# GD32VF103 register map
File version: 1.0
CPU: r2p1, little endian, no MPU, no FPU, 4 interrupt priority bits
Registers are 32-bit, read-write, reset 0x0 unless marked. A register's access mark holds for its fields unless they carry their own. Offsets are from the block's base; [hi:lo] are bit positions; {n}, {i} and the like mark numbered series.

## CPU_TIMER
Base 0xD1000000
0x00 MTIME_LO — mtime low register
  [31:0] COUNT — MTIME count
0x04 MTIME_HI — mtime high register
  [31:0] COUNT — MTIME count
0x08 MTIMECMP_LO reset 0xFFFFFFFF — mtimecmp low register
  [31:0] COUNT — MTIMECMP count
0x0C MTIMECMP_HI reset 0xFFFFFFFF — mtimecmp high register
  [31:0] COUNT — MTIMECMP count
0xFF8 MSTOP
  [0] TIMESTOP
0xFFC MSIP
  [0] MSIP

## ECLIC — Enhanced Core Local Interrupt Controller
Base 0xD2000000
0x00 CLICCFG 8-bit
  [4:1] NLBITS
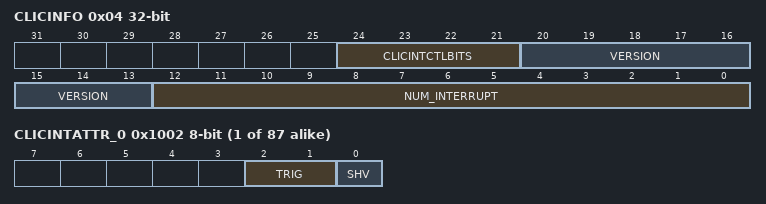
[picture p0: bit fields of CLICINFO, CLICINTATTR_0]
0x04 CLICINFO ro
  [24:21] CLICINTCTLBITS, [20:13] VERSION, [12:0] NUM_INTERRUPT
0x0B MTH 8-bit
{0x1000+4i} CLICINTIP_{i} 8-bit (i=0..84) — clicintip Register
  [0] IP
{0x1001+4i} CLICINTIE_{i} 8-bit (i=0..86) — clicintie Register
  [0] IE
{0x1002+4i} CLICINTATTR_{i} 8-bit (i=0..86) — clicintattr Register
  [2:1] TRIG, [0] SHV
{0x1003+4i} CLICINTCTL_{i} 8-bit (i=0..86) — clicintctl Register
  [7:0] LEVEL_PRIORITY
0x1158 CLICINTIP_85 8-bit — clicintip Register
  [0] IP
0x115C CLICINTIP_86 8-bit — clicintip Register
  [0] IP

## PMU — Power management unit
Base 0x40007000
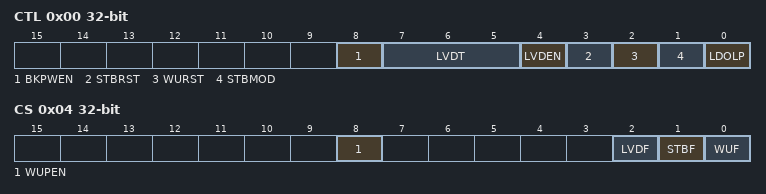
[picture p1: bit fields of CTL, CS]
0x00 CTL — power control register
  [8] BKPWEN — Backup Domain Write Enable
  [7:5] LVDT — Low Voltage Detector Threshold
  [4] LVDEN — Low Voltage Detector Enable
  [3] STBRST — Standby Flag Reset
  [2] WURST — Wakeup Flag Reset
  [1] STBMOD — Standby Mode
  [0] LDOLP — LDO Low Power Mode
0x04 CS access per field — power control/status register
  [8] WUPEN rw — Enable WKUP pin
  [2] LVDF ro — Low Voltage Detector Status Flag
  [1] STBF ro — Standby flag
  [0] WUF ro — Wakeup flag

## RTC — Real-time clock
Base 0x40002800
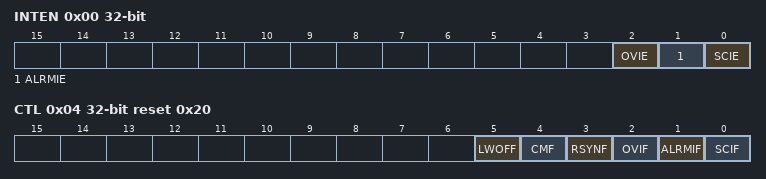
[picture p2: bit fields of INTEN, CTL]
0x00 INTEN — RTC interrupt enable register
  [2] OVIE — Overflow interrupt enable
  [1] ALRMIE — Alarm interrupt enable
  [0] SCIE — Second interrupt
0x04 CTL reset 0x20 — control register
  [5] LWOFF — Last write operation finished flag
  [4] CMF — Configuration mode flag
  [3] RSYNF — Registers synchronized flag
  [2] OVIF — Overflow interrupt flag
  [1] ALRMIF — Alarm interrupt flag
  [0] SCIF — Sencond interrupt flag
0x08 PSCH write — RTC prescaler high register
  [3:0] PSC — RTC prescaler value high
0x0C PSCL write reset 0x8000 — RTC prescaler low register
  [15:0] PSC — RTC prescaler value low
0x10 DIVH ro — RTC divider high register
  [3:0] DIV — RTC divider value high
0x14 DIVL ro reset 0x8000 — RTC divider low register
  [15:0] DIV — RTC divider value low
0x18 CNTH — RTC counter high register
  [15:0] CNT — RTC counter value high
0x1C CNTL — RTC counter low register
  [15:0] CNT — RTC counter value low
0x20 ALRMH write reset 0xFFFF — Alarm high register
  [15:0] ALRM — Alarm value high
0x24 ALRML write reset 0xFFFF — RTC alarm low register
  [15:0] ALRM — alarm value low

## SPI0 — Serial peripheral interface
Base 0x40013000
Same registers: SPI1 0x40003800, SPI2 0x40003C00
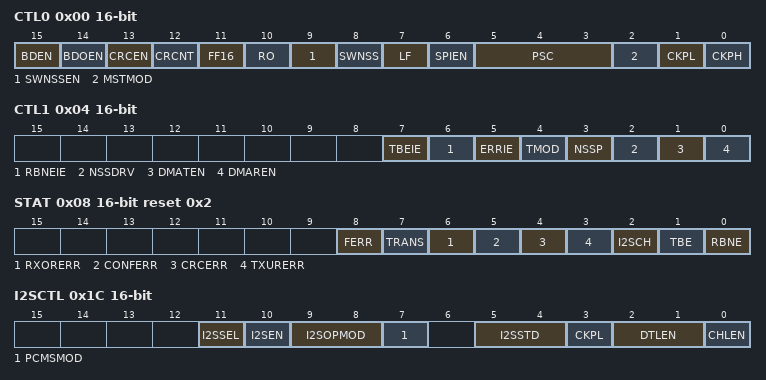
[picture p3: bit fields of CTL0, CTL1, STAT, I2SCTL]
0x00 CTL0 16-bit — control register 0
  [15] BDEN — Bidirectional enable
  [14] BDOEN — Bidirectional Transmit output enable
  [13] CRCEN — CRC Calculation Enable
  [12] CRCNT — CRC Next Transfer
  [11] FF16 — Data frame format
  [10] RO — Receive only
  [9] SWNSSEN — NSS Software Mode Selection
  [8] SWNSS — NSS Pin Selection In NSS Software Mode
  [7] LF — LSB First Mode
  [6] SPIEN — SPI enable
  [5:3] PSC — Master Clock Prescaler Selection
  [2] MSTMOD — Master Mode Enable
  [1] CKPL — Clock polarity Selection
  [0] CKPH — Clock Phase Selection
0x04 CTL1 16-bit — control register 1
  [7] TBEIE — Tx buffer empty interrupt enable
  [6] RBNEIE — RX buffer not empty interrupt enable
  [5] ERRIE — Error interrupt enable
  [4] TMOD — SPI TI mode enable
  [3] NSSP — SPI NSS pulse mode enable
  [2] NSSDRV — Drive NSS Output
  [1] DMATEN — Transmit Buffer DMA Enable
  [0] DMAREN — Rx buffer DMA enable
0x08 STAT 16-bit access per field reset 0x2 — status register
  [8] FERR ro — Format error
  [7] TRANS ro — Transmitting On-going Bit
  [6] RXORERR ro — Reception Overrun Error Bit
  [5] CONFERR ro — SPI Configuration error
  [4] CRCERR rw — SPI CRC Error Bit
  [3] TXURERR ro — Transmission underrun error bit
  [2] I2SCH ro — I2S channel side
  [1] TBE ro — Transmit Buffer Empty
  [0] RBNE ro — Receive Buffer Not Empty
0x0C DATA 16-bit
  [15:0] SPI_DATA — Data transfer register
0x10 CRCPOLY 16-bit reset 0x7 — CRC polynomial register
  [15:0] CRCPOLY — CRC polynomial value
0x14 RCRC 16-bit ro — RX CRC register
  [15:0] RCRC — RX CRC value
0x18 TCRC 16-bit ro — TX CRC register
  [15:0] TCRC — Tx CRC value
0x1C I2SCTL 16-bit — I2S control register
  [11] I2SSEL — I2S mode selection
  [10] I2SEN — I2S Enable
  [9:8] I2SOPMOD — I2S operation mode
  [7] PCMSMOD — PCM frame synchronization mode
  [5:4] I2SSTD — I2S standard selection
  [3] CKPL — Idle state clock polarity
  [2:1] DTLEN — Data length
  [0] CHLEN — Channel length (number of bits per audio channel)
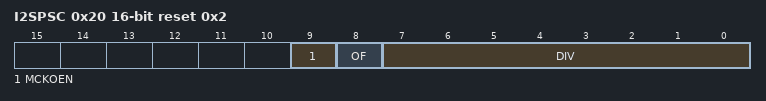
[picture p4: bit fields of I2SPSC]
0x20 I2SPSC 16-bit reset 0x2 — I2S prescaler register
  [9] MCKOEN — I2S_MCK output enable
  [8] OF — Odd factor for the prescaler
  [7:0] DIV — Dividing factor for the prescaler
